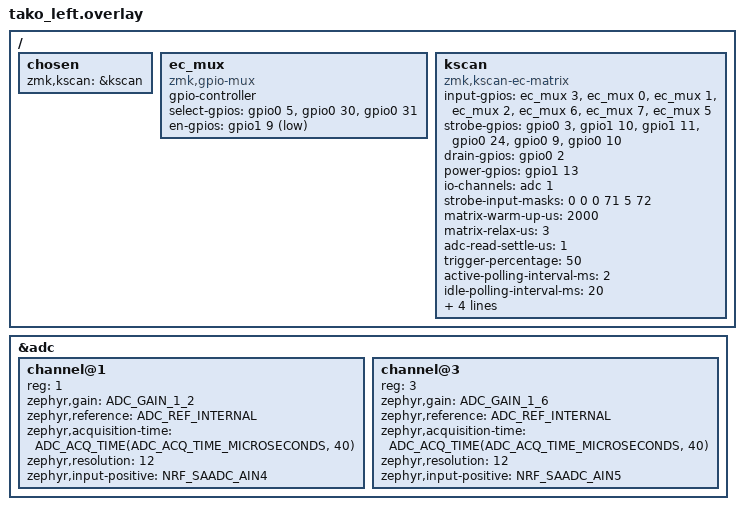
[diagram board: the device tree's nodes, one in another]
/*
 * Copyright (c) 2023 ssbb
 *
 * SPDX-License-Identifier: MIT
 */

#include <zephyr/dt-bindings/adc/adc.h>
#include <zephyr/dt-bindings/dt-util.h>
#include <zephyr/dt-bindings/gpio/nordic-nrf-gpio.h>

#include "tako.dtsi"

/ {
  chosen {
    zmk,kscan = &kscan;
  };

  ec_mux: ec_mux {
    compatible = "zmk,gpio-mux";
    gpio-controller;
    #gpio-cells = <2>;

    select-gpios
    = <&gpio0 5 GPIO_ACTIVE_HIGH>
    , <&gpio0 30 GPIO_ACTIVE_HIGH>
    , <&gpio0 31 GPIO_ACTIVE_HIGH>
    ;

    /* 74HC4051 INH/enable is active-low on the Tako EC circuit. */
    en-gpios = <&gpio1 9 GPIO_ACTIVE_LOW>;
  };

  kscan: kscan {
    compatible = "zmk,kscan-ec-matrix";

    input-gpios
    = <&ec_mux 3 0>
    , <&ec_mux 0 0>
    , <&ec_mux 1 0>
    , <&ec_mux 2 0>
    , <&ec_mux 6 0>
    , <&ec_mux 7 0>
    , <&ec_mux 5 0>
    ;

    strobe-gpios
    = <&gpio0 3 (GPIO_ACTIVE_HIGH | NRF_GPIO_DRIVE_H0H1)>
    , <&gpio1 10 (GPIO_ACTIVE_HIGH | NRF_GPIO_DRIVE_H0H1)>
    , <&gpio1 11 (GPIO_ACTIVE_HIGH | NRF_GPIO_DRIVE_H0H1)>
    , <&gpio0 24 (GPIO_ACTIVE_HIGH | NRF_GPIO_DRIVE_H0H1)>
    , <&gpio0 9 (GPIO_ACTIVE_HIGH | NRF_GPIO_DRIVE_H0H1)>
    , <&gpio0 10 (GPIO_ACTIVE_HIGH | NRF_GPIO_DRIVE_H0H1)>
    ;

    drain-gpios = <&gpio0 2 (GPIO_ACTIVE_HIGH | NRF_GPIO_DRIVE_H0H1)>;
    power-gpios = <&gpio1 13 (GPIO_ACTIVE_HIGH | NRF_GPIO_DRIVE_H0H1)>;
    io-channels = <&adc 1>;

    /* Bits set to 1 are empty matrix positions to skip during scan/calibration. */
    strobe-input-masks = <0 0 0 71 5 72>;

    matrix-warm-up-us = <2000>;
    matrix-relax-us = <3>;
    adc-read-settle-us = <1>;

    trigger-percentage = <50>;
    active-polling-interval-ms = <2>;
    idle-polling-interval-ms = <20>;
    sleep-polling-interval-ms = <200>;
    idle-after-secs = <5>;
    sleep-after-secs = <300>;
    dynamic-polling-interval;
  };
};

&adc {
  #address-cells = <1>;
  #size-cells = <0>;
  status = "okay";

  // EC Read
  channel@1 {
    reg = <1>;
    /* Raises 700-800 old raw readings above Pete EC calibrator's 2048 high threshold. */
    zephyr,gain = "ADC_GAIN_1_2";
    zephyr,reference = "ADC_REF_INTERNAL";
    zephyr,acquisition-time = <ADC_ACQ_TIME(ADC_ACQ_TIME_MICROSECONDS, 40)>;
    zephyr,resolution = <12>;
    zephyr,input-positive = <NRF_SAADC_AIN4>; /* P0.28 */
  };

  // Battery Sensing
  channel@3 {
    reg = <3>;
    zephyr,gain = "ADC_GAIN_1_6";
    zephyr,reference = "ADC_REF_INTERNAL";
    zephyr,acquisition-time = <ADC_ACQ_TIME(ADC_ACQ_TIME_MICROSECONDS, 40)>;
    zephyr,resolution = <12>;
    zephyr,input-positive = <NRF_SAADC_AIN5>; /* P0.29 */
  };
};
